# f28e12x_dma_cla_src_sel_regs register map
Vendor: Texas Instruments
Peripheral module from a debugger description file (folder C2000).
Address unit: 16 bits
Registers are 32-bit, read-write, no defined reset value unless marked. A register's access mark holds for its fields unless they carry their own. Offsets are as the file gives them; lines under a group give offsets from that group; [hi:lo] are bit positions; {n}, {i} and the like mark numbered series; 'fields as' and 'values as' point back to an identical list; <NAME> marks a mode.

## DMA_CLA_SRC_SEL_REGS — DMA CLA SRC SEL Registers
0x00 DMACLASRCSELLOCK — DMA/CLA Trigger Source Select Lock Register
  [0] ALL — DMACLASRCSEL Registers Lock bit
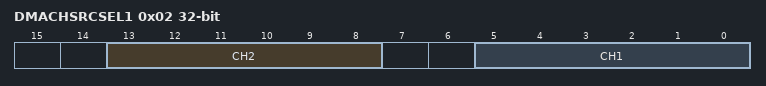
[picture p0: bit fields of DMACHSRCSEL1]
0x02 DMACHSRCSEL1 — DMA Channel Trigger Source Select Register-1
  [13:8] CH2 — Selects the Trigger and Sync Source CH2 of DMA
  [5:0] CH1 — Selects the Trigger and Sync Source CH1 of DMA
